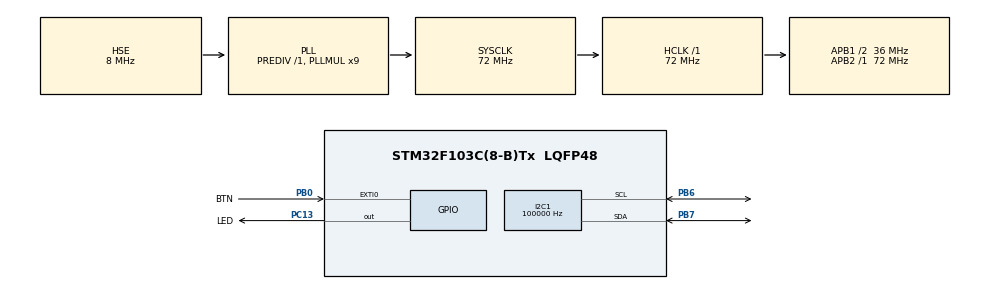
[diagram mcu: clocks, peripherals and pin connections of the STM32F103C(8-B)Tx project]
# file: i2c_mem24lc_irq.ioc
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I2C1.ClockSpeed=100000
Mcu.Family=STM32F1
Mcu.Name=STM32F103C(8-B)Tx
Mcu.Package=LQFP48
NVIC.EXTI0_IRQn=true\:0\:0\:false\:false\:true\:true\:true\:true
NVIC.I2C1_EV_IRQn=true\:0\:0\:false\:false\:true\:true\:true\:true
NVIC.PriorityGroup=NVIC_PRIORITYGROUP_4
PA13.Mode=Serial_Wire
PA13.Signal=SYS_JTMS-SWDIO
PA14.Mode=Serial_Wire
PA14.Signal=SYS_JTCK-SWCLK
PB0.GPIO_Label=BTN
PB0.GPIO_ModeDefaultEXTI=GPIO_MODE_IT_FALLING
PB0.GPIO_PuPd=GPIO_PULLUP
PB0.Signal=GPXTI0
PB6.Mode=I2C
PB6.Signal=I2C1_SCL
PB7.Mode=I2C
PB7.Signal=I2C1_SDA
PC13-TAMPER-RTC.GPIO_Label=LED
PC13-TAMPER-RTC.Signal=GPIO_Output
PD0-OSC_IN.Mode=HSE-External-Oscillator
PD0-OSC_IN.Signal=RCC_OSC_IN
PD1-OSC_OUT.Mode=HSE-External-Oscillator
PD1-OSC_OUT.Signal=RCC_OSC_OUT
ProjectManager.HeapSize=0x200
ProjectManager.StackSize=0x400
ProjectManager.TargetToolchain=STM32CubeIDE
RCC.AHBFreq_Value=72000000
RCC.APB1CLKDivider=RCC_HCLK_DIV2
RCC.APB1Freq_Value=36000000
RCC.APB1TimFreq_Value=72000000
RCC.APB2Freq_Value=72000000
RCC.APB2TimFreq_Value=72000000
RCC.HCLKFreq_Value=72000000
RCC.PLLMUL=RCC_PLL_MUL9
RCC.PLLSourceVirtual=RCC_PLLSOURCE_HSE
RCC.SYSCLKFreq_VALUE=72000000
RCC.SYSCLKSource=RCC_SYSCLKSOURCE_PLLCLK
RCC.USBFreq_Value=72000000
board=custom

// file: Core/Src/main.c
/* USER CODE BEGIN Header */
/**
 ******************************************************************************
 * @file           : main.c
 * @brief          : Main program body
 ******************************************************************************
 * @attention
 *
 * Copyright (c) 2022 STMicroelectronics.
 * All rights reserved.
 *
 * This software is licensed under terms that can be found in the LICENSE file
 * in the root directory of this software component.
 * If no LICENSE file comes with this software, it is provided AS-IS.
 *
 ******************************************************************************
 */
/* USER CODE END Header */
#include "main.h"

/* USER CODE BEGIN Includes */
#include "mem24lc.h"
#include "user_gpio.h"
/* USER CODE END Includes */

I2C_HandleTypeDef hi2c1;

/* USER CODE BEGIN PV */
static uint16_t mem_read_value;
/* USER CODE END PV */

void SystemClock_Config(void);
static void MX_GPIO_Init(void);
static void MX_I2C1_Init(void);

/* USER CODE BEGIN 0 */

void HAL_IncTick(void)
{
	uwTick += uwTickFreq;
	mem24lc_tick();
	user_gpio_tick();
}

void mem24lc_read_callback(void)
{
	user_gpio_set_led_delay_ms(mem_read_value);
}

/* USER CODE END 0 */

int main(void)
{

	/* MCU Configuration--------------------------------------------------------*/

	/* Reset of all peripherals, Initializes the Flash interface and the Systick. */
	HAL_Init();

	/* Configure the system clock */
	SystemClock_Config();

	/* Initialize all configured peripherals */
	MX_GPIO_Init();
	MX_I2C1_Init();

	/* Infinite loop */
	/* USER CODE BEGIN WHILE */
	mem24lc_read(MEM_ADDRESS, &mem_read_value, sizeof(mem_read_value));

	while (1)
	{
		mem24lc_loop();
		user_gpio_loop();

		__WFI();

		/* USER CODE END WHILE */

	}
}

void SystemClock_Config(void)
{
	RCC_OscInitTypeDef RCC_OscInitStruct = {0};
	RCC_ClkInitTypeDef RCC_ClkInitStruct = {0};

	/** Initializes the RCC Oscillators according to the specified parameters
	 * in the RCC_OscInitTypeDef structure.
	 */
	RCC_OscInitStruct.OscillatorType = RCC_OSCILLATORTYPE_HSE;
	RCC_OscInitStruct.HSEState = RCC_HSE_ON;
	RCC_OscInitStruct.HSEPredivValue = RCC_HSE_PREDIV_DIV1;
	RCC_OscInitStruct.HSIState = RCC_HSI_ON;
	RCC_OscInitStruct.PLL.PLLState = RCC_PLL_ON;
	RCC_OscInitStruct.PLL.PLLSource = RCC_PLLSOURCE_HSE;
	RCC_OscInitStruct.PLL.PLLMUL = RCC_PLL_MUL9;
	if (HAL_RCC_OscConfig(&RCC_OscInitStruct) != HAL_OK)
	{
		Error_Handler();
	}

	/** Initializes the CPU, AHB and APB buses clocks
	 */
	RCC_ClkInitStruct.ClockType = RCC_CLOCKTYPE_HCLK|RCC_CLOCKTYPE_SYSCLK
			|RCC_CLOCKTYPE_PCLK1|RCC_CLOCKTYPE_PCLK2;
	RCC_ClkInitStruct.SYSCLKSource = RCC_SYSCLKSOURCE_PLLCLK;
	RCC_ClkInitStruct.AHBCLKDivider = RCC_SYSCLK_DIV1;
	RCC_ClkInitStruct.APB1CLKDivider = RCC_HCLK_DIV2;
	RCC_ClkInitStruct.APB2CLKDivider = RCC_HCLK_DIV1;

	if (HAL_RCC_ClockConfig(&RCC_ClkInitStruct, FLASH_LATENCY_2) != HAL_OK)
	{
		Error_Handler();
	}
}

static void MX_I2C1_Init(void)
{

	hi2c1.Instance = I2C1;
	hi2c1.Init.ClockSpeed = 100000;
	hi2c1.Init.DutyCycle = I2C_DUTYCYCLE_2;
	hi2c1.Init.OwnAddress1 = 0;
	hi2c1.Init.AddressingMode = I2C_ADDRESSINGMODE_7BIT;
	hi2c1.Init.DualAddressMode = I2C_DUALADDRESS_DISABLE;
	hi2c1.Init.OwnAddress2 = 0;
	hi2c1.Init.GeneralCallMode = I2C_GENERALCALL_DISABLE;
	hi2c1.Init.NoStretchMode = I2C_NOSTRETCH_DISABLE;
	if (HAL_I2C_Init(&hi2c1) != HAL_OK)
	{
		Error_Handler();
	}

}

static void MX_GPIO_Init(void)
{
	GPIO_InitTypeDef GPIO_InitStruct = {0};

	/* GPIO Ports Clock Enable */
	__HAL_RCC_GPIOC_CLK_ENABLE();
	__HAL_RCC_GPIOD_CLK_ENABLE();
	__HAL_RCC_GPIOB_CLK_ENABLE();
	__HAL_RCC_GPIOA_CLK_ENABLE();

	/*Configure GPIO pin Output Level */
	HAL_GPIO_WritePin(LED_GPIO_Port, LED_Pin, GPIO_PIN_RESET);

	/*Configure GPIO pin : LED_Pin */
	GPIO_InitStruct.Pin = LED_Pin;
	GPIO_InitStruct.Mode = GPIO_MODE_OUTPUT_PP;
	GPIO_InitStruct.Pull = GPIO_NOPULL;
	GPIO_InitStruct.Speed = GPIO_SPEED_FREQ_LOW;
	HAL_GPIO_Init(LED_GPIO_Port, &GPIO_InitStruct);

	/*Configure GPIO pin : BTN_Pin */
	GPIO_InitStruct.Pin = BTN_Pin;
	GPIO_InitStruct.Mode = GPIO_MODE_IT_FALLING;
	GPIO_InitStruct.Pull = GPIO_PULLUP;
	HAL_GPIO_Init(BTN_GPIO_Port, &GPIO_InitStruct);

	/* EXTI interrupt init*/
	HAL_NVIC_SetPriority(EXTI0_IRQn, 0, 0);
	HAL_NVIC_EnableIRQ(EXTI0_IRQn);

}

void Error_Handler(void)
{
	__disable_irq();
	while (1)
	{
	}
}
